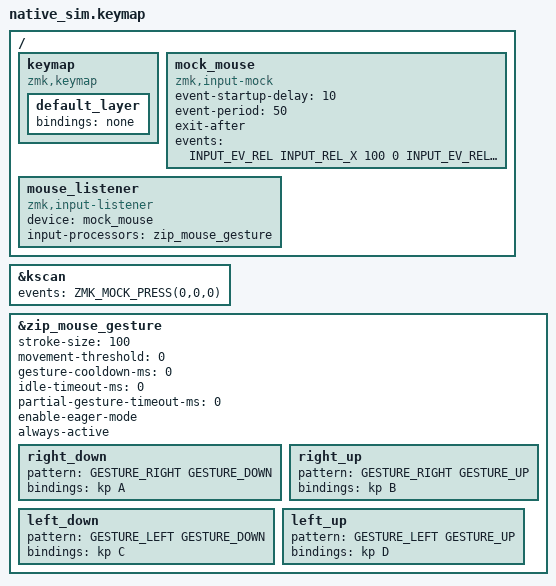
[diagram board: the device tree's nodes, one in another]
#include "../../behavior_keymap.dtsi"

/ {
    keymap {
        compatible = "zmk,keymap";
        default_layer {
            bindings = <&none>;
        };
    };

    mock_mouse: mock_mouse {
        compatible = "zmk,input-mock";
        event-startup-delay = <10>;
        event-period = <50>;
        exit-after;
        events = <
            INPUT_EV_REL INPUT_REL_X 100 0
            INPUT_EV_REL INPUT_REL_Y 100 1
            INPUT_EV_REL INPUT_REL_X 100 0
            INPUT_EV_REL INPUT_REL_Y (-100) 1
            INPUT_EV_REL INPUT_REL_X (-100) 0
            INPUT_EV_REL INPUT_REL_Y 100 1
            INPUT_EV_REL INPUT_REL_X (-100) 0
            INPUT_EV_REL INPUT_REL_Y (-100) 1
            INPUT_EV_REL INPUT_REL_WHEEL 0 1
        >;
    };

    mouse_listener: mouse_listener {
        compatible = "zmk,input-listener";
        device = <&mock_mouse>;
        input-processors = <&zip_mouse_gesture>;
    };
};

&kscan {
    events = <ZMK_MOCK_PRESS(0,0,0)>;
    /delete-property/ exit-after;
};

&zip_mouse_gesture {
    stroke-size = <100>;
    movement-threshold = <0>;
    gesture-cooldown-ms = <0>;
    idle-timeout-ms = <0>;
    partial-gesture-timeout-ms = <0>;
    enable-eager-mode;
    always-active;

    right_down {
        pattern = <GESTURE_RIGHT GESTURE_DOWN>;
        bindings = <&kp A>;
    };
    right_up {
        pattern = <GESTURE_RIGHT GESTURE_UP>;
        bindings = <&kp B>;
    };
    left_down {
        pattern = <GESTURE_LEFT GESTURE_DOWN>;
        bindings = <&kp C>;
    };
    left_up {
        pattern = <GESTURE_LEFT GESTURE_UP>;
        bindings = <&kp D>;
    };
};
